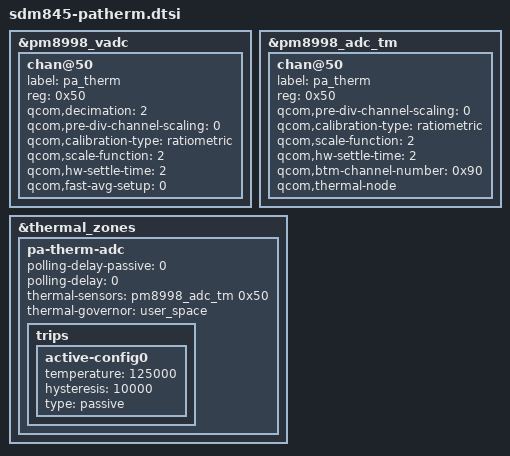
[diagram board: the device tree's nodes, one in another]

&pm8998_vadc {
	chan@50 {
		label = "pa_therm";
		reg = <0x50>;
		qcom,decimation = <2>;
		qcom,pre-div-channel-scaling = <0>;
		qcom,calibration-type = "ratiometric";
		qcom,scale-function = <2>;
		qcom,hw-settle-time = <2>;
		qcom,fast-avg-setup = <0>;
	};
};

&pm8998_adc_tm {
	chan@50 {
		label = "pa_therm";
		reg = <0x50>;
		qcom,pre-div-channel-scaling = <0>;
		qcom,calibration-type = "ratiometric";
		qcom,scale-function = <2>;
		qcom,hw-settle-time = <2>;
		qcom,btm-channel-number = <0x90>;
		qcom,thermal-node;
	};
};

&thermal_zones {
	pa-therm-adc {
		polling-delay-passive = <0>;
		polling-delay = <0>;
		thermal-sensors = <&pm8998_adc_tm 0x50>;
		thermal-governor = "user_space";

		trips {
			active-config0 {
				temperature = <125000>;
				hysteresis = <10000>;
				type = "passive";
			};
		};
	};
};
